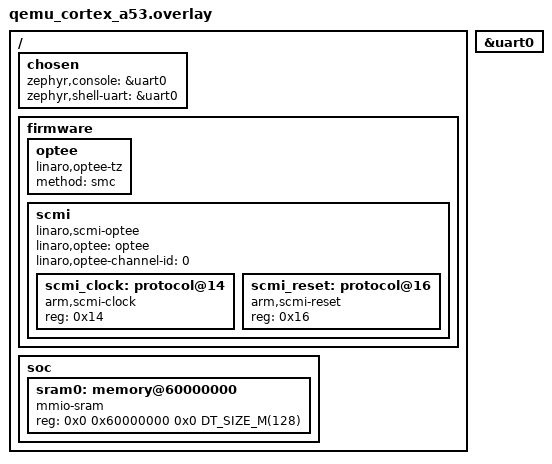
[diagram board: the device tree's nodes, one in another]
/*
 * Copyright (c) 2026 EPAM Systems
 *
 * SPDX-License-Identifier: Apache-2.0
 */

/ {
	chosen {
		zephyr,console = &uart0;
		zephyr,shell-uart = &uart0;
	};

	firmware {
		optee: optee {
			compatible = "linaro,optee-tz";
			method = "smc";
			status = "okay";
		};

		scmi {
			compatible = "linaro,scmi-optee";
			#address-cells = <1>;
			#size-cells = <0>;
			linaro,optee = <&optee>;
			linaro,optee-channel-id = <0>;

			scmi_clock: protocol@14 {
				compatible = "arm,scmi-clock";
				reg = <0x14>;
				#clock-cells = <1>;
			};

			scmi_reset: protocol@16 {
				compatible = "arm,scmi-reset";
				reg = <0x16>;
				#reset-cells = <1>;
			};
		};
	};

	soc {
		/delete-node/ memory@40000000;

		sram0: memory@60000000 {
			compatible = "mmio-sram";
			reg = <0x0 0x60000000 0x0 DT_SIZE_M(128)>;
		};
	};
};

&uart0 {
	status = "okay";
};
